# GD32H71x_72x register map
File version: 1.0
CPU: CM7 r1p2, little endian, MPU, FPU, 4 interrupt priority bits
Registers are 32-bit, read-write, reset 0x0 unless marked. A register's access mark holds for its fields unless they carry their own. Offsets are from the block's base; [hi:lo] are bit positions; {n}, {i} and the like mark numbered series.

## DBG — Debug
Base 0xE00E1000
0x00 ID ro — ID code register
  [31:0] ID_CODE — DBG ID code register
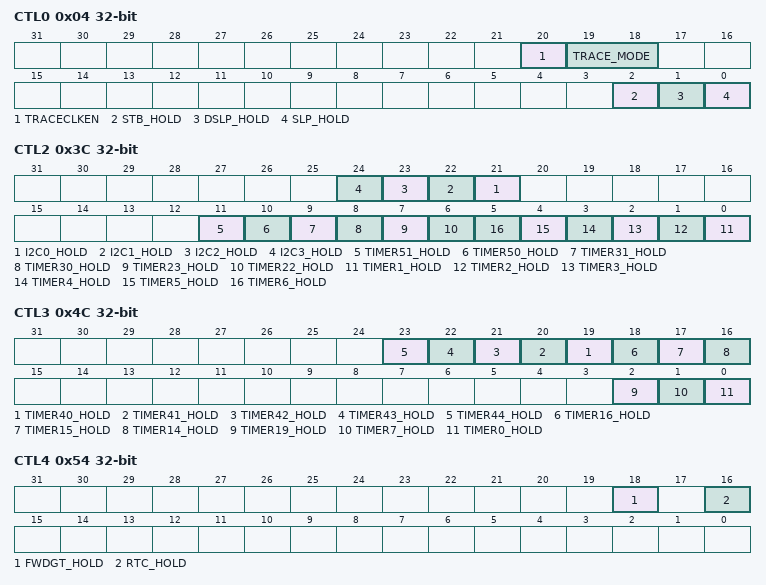
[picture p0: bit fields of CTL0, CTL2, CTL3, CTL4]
0x04 CTL0 — Control register0
  [20] TRACECLKEN — Trace port clock enable
  [19:18] TRACE_MODE — Trace pin allocation mode
  [2] STB_HOLD — Standby mode hold bit
  [1] DSLP_HOLD — Deep-sleep mode hold bit
  [0] SLP_HOLD — Sleep mode hold bit
0x34 CTL1 — Control register1
  [6] WWDGT_HOLD — WWDGT hold bit
0x3C CTL2 — Control register2
  [n+21] I2C{n}_HOLD (n=0..3) — I2C{n} hold bit
  [11] TIMER51_HOLD — TIMER51 hold bit
  [10] TIMER50_HOLD — TIMER50 hold bit
  [9] TIMER31_HOLD — TIMER31 hold bit
  [8] TIMER30_HOLD — TIMER30 hold bit
  [7] TIMER23_HOLD — TIMER23 hold bit
  [6] TIMER22_HOLD — TIMER22 hold bit
  [n-1] TIMER{n}_HOLD (n=1..6) — TIMER{n} hold bit
0x4C CTL3 — Control register3
  [n-21] TIMER{n}_HOLD (n=40..44) — TIMER{n} hold bit
  [18] TIMER16_HOLD — TIMER16 hold bit
  [17] TIMER15_HOLD — TIMER15 hold bit
  [16] TIMER14_HOLD — TIMER14 hold bit
  [2] TIMER19_HOLD — TIMER19 hold bit
  [1] TIMER7_HOLD — TIMER7 hold bit
  [0] TIMER0_HOLD — TIMER0 hold bit
0x54 CTL4 — Control register4
  [18] FWDGT_HOLD — FWDGT hold bit
  [16] RTC_HOLD — RTC hold bit

## DMAMUX — DMA request multiplexer
Base 0x40020800
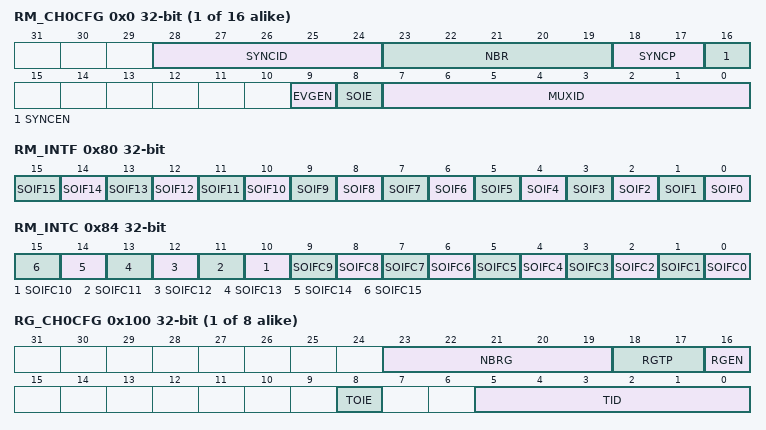
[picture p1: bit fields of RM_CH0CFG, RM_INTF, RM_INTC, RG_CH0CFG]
{0x0+4i} RM_CH{i}CFG (i=0..15) — Request multiplexer channel {i} configuration regist
  [28:24] SYNCID — Synchronization input identification
  [23:19] NBR — Number of DMA requests to forward
  [18:17] SYNCP — Synchronization input polarity
  [16] SYNCEN — Synchronization enable
  [9] EVGEN — Event generation enable
  [8] SOIE — Synchronization overrun interrupt enable
  [7:0] MUXID — Multiplexer input identification
0x80 RM_INTF ro — Request multiplexer channel interrupt flag register
  [n] SOIF{n} (n=0..15) — Synchronization overrun event flag of request multiplexer channel {n}
0x84 RM_INTC wo — Request multiplexer channel interrupt flag clear register
  [n] SOIFC{n} (n=0..15) — Clear bit for synchronization overrun event flag of request multiplexer channel {n}
{0x100+4i} RG_CH{i}CFG (i=0..7) — Request generator channel {i} configuration regist
  [23:19] NBRG — Number of DMA requests to be generated
  [18:17] RGTP — DMAMUX request generator trigger polarity
  [16] RGEN — DMAMUX request generator channel x enable
  [8] TOIE — Trigger overrun interrupt enable
  [5:0] TID — Trigger input identification
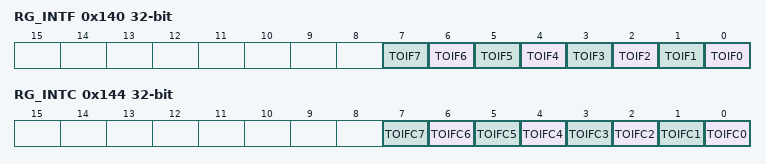
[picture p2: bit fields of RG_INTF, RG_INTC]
0x140 RG_INTF ro — Request generator channel interrupt flag register
  [n] TOIF{n} (n=0..7) — Trigger overrun event flag of request generator channel {n}
0x144 RG_INTC wo — Rquest generator channel interrupt flag clear register
  [n] TOIFC{n} (n=0..7) — Clear bit for trigger overrun event flag of request generator channel {n}

## EDIM — Encoder Interface Module
Base 0x4000D400
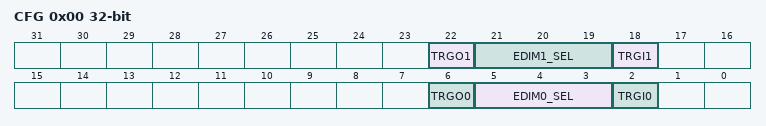
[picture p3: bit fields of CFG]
0x00 CFG — EDIM configuration register
  [22] TRGO1 — Trigger signal output to EDIM0 from EDIM1 selection
  [21:19] EDIM1_SEL — Encoder selection for EDIM1 I/O
  [18] TRGI1 — Trigger signal for active encoder in EDIM1 selection
  [6] TRGO0 — Trigger signal output to EDIM1 from EDIM0 selection
  [5:3] EDIM0_SEL — Encoder selection for EDIM0 I/O
  [2] TRGI0 — Trigger signal for active encoder in EDIM0 selection

## EDOUT — Encoder Divided-Output controller
Base 0x40017800
0x00 CTL — Control register
  [0] POL — B-Phase active polarity
0x04 ENABLE
  [0] EDOUTEN — EDOUT enable bit.
0x08 LOC reset 0xFFFF — Location register
  [15:0] LOCMAX — Maximum location value
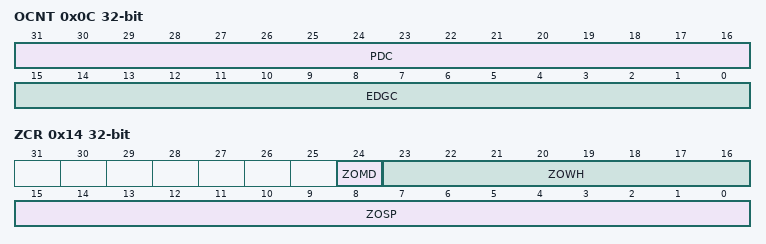
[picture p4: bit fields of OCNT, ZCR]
0x0C OCNT — Output counter register
  [31:16] PDC — Phase difference count
  [15:0] EDGC — Edge count
0x10 LCNT — Location counter register
  [15:0] LOCCNT — Current location value
0x14 ZCR — Z-phase configure register
  [24] ZOMD — Z-phase output mode
  [23:16] ZOWH — Z-phase output width
  [15:0] ZOSP — Z-phase output start location
